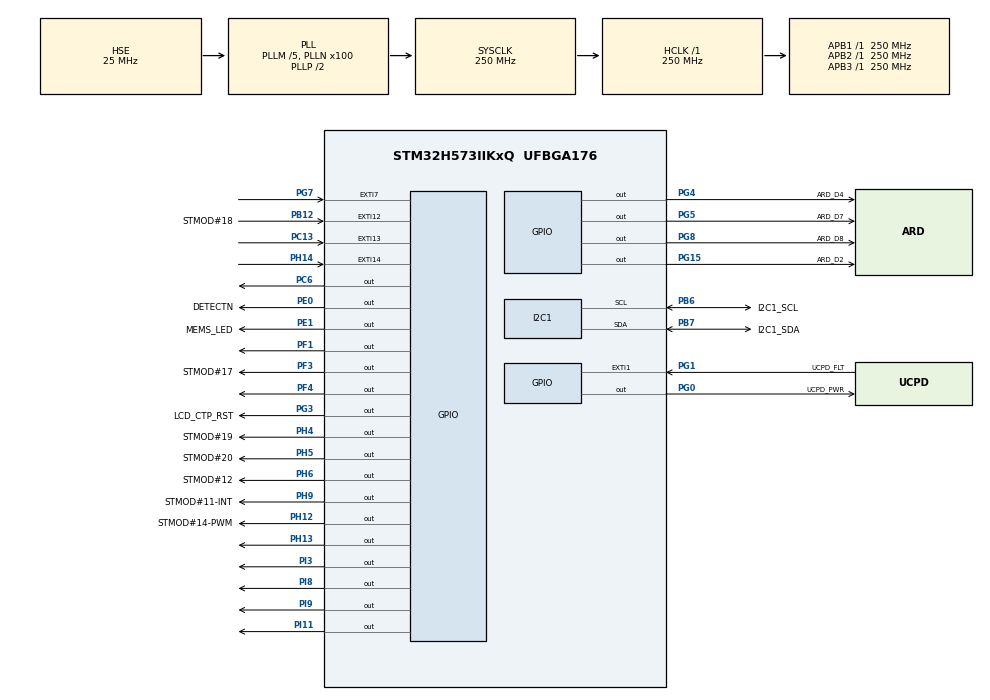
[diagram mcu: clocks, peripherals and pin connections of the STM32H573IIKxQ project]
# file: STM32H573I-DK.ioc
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BOOTPATH.BootPathName=LEGACY
BOOTPATH.UserSelectedBootPath=LEGACY
CORTEX_M33_NS.userName=CORTEX_M33
I2C1.Timing=0x60808CD3
Mcu.Family=STM32H5
Mcu.Name=STM32H573IIKxQ
Mcu.Package=UFBGA176
NVIC.EXTI13_IRQn=true\:0\:0\:false\:false\:true\:false\:true\:true
NVIC.EXTI14_IRQn=true\:0\:0\:false\:false\:true\:false\:true\:true
NVIC.EXTI7_IRQn=true\:0\:0\:false\:false\:true\:false\:true\:true
NVIC.PriorityGroup=NVIC_PRIORITYGROUP_4
PA0.GPIO_Label=ARD_A2
PA0.Signal=ADCx_INP0
PA1.GPIO_Label=RMII_REF_CLK
PA1.Signal=ETH_REF_CLK
PA10.Signal=USART1_RX
PA11.GPIO_Label=USB_FS_N
PA11.Signal=USB_DM
PA12.GPIO_Label=USB_FS_P
PA12.Signal=USB_DP
PA13(JTMS/SWDIO).GPIO_Label=JTMS
PA13(JTMS/SWDIO).Signal=DEBUG_JTMS-SWDIO
PA14(JTCK/SWCLK).GPIO_Label=JTCK
PA14(JTCK/SWCLK).Signal=DEBUG_JTCK-SWCLK
PA15(JTDI).GPIO_Label=JTDI
PA15(JTDI).Signal=DEBUG_JTDI
PA2.GPIO_Label=RMII_MDIO
PA2.Signal=ETH_MDIO
PA3.GPIO_Label=ARD_D10
PA3.Signal=SPI2_NSS
PA4.GPIO_Label=ARD_A1
PA4.Signal=ADCx_INP18
PA5.GPIO_Label=ARD_A3
PA5.Signal=ADCx_INP19
PA6.GPIO_Label=ARD_A4
PA6.Signal=ADCx_INP3
PA7.GPIO_Label=RMII_CRS_DV
PA7.Signal=ETH_CRS_DV
PA8.GPIO_Label=ARD_D9
PA8.Signal=S_TIM1_CH1
PA9.Signal=USART1_TX
PB0.GPIO_Label=ARD_A0
PB0.Signal=ADCx_INP9
PB1.Signal=OCTOSPI1_IO0
PB10.GPIO_Label=ARD_D1
PB10.Signal=USART3_TX
PB11.GPIO_Label=ARD_D0
PB11.Signal=USART3_RX
PB12.GPIO_Label=STMOD\#18
PB12.Signal=GPXTI12
PB13.GPIO_Label=UCPD_CC1
PB13.Signal=UCPD1_CC1
PB14.GPIO_Label=UCPD_CC2
PB14.Signal=UCPD1_CC2
PB15.GPIO_Label=ARD_D11
PB15.Signal=SPI2_MOSI
PB2.Signal=OCTOSPI1_DQS
PB3(JTDO/TRACESWO).GPIO_Label=SWO
PB3(JTDO/TRACESWO).Signal=DEBUG_JTDO-SWO
PB4(NJTRST).GPIO_Label=NJTRST
PB4(NJTRST).Signal=DEBUG_JTRST
PB5.GPIO_Label=ARD_D3
PB5.Signal=S_TIM3_CH2
PB6.GPIO_Label=I2C1_SCL
PB6.Mode=I2C
PB6.Signal=I2C1_SCL
PB7.GPIO_Label=I2C1_SDA
PB7.Mode=I2C
PB7.Signal=I2C1_SDA
PC0.Signal=OCTOSPI1_IO7
PC1.GPIO_Label=RMII_MDC
PC1.Signal=ETH_MDC
PC10.Signal=SDMMC1_D2
PC11.Signal=SDMMC1_D3
PC12.Signal=SDMMC1_CK
PC13.Signal=GPXTI13
PC14-OSC32_IN(OSC32_IN).Signal=RCC_OSC32_IN
PC15-OSC32_OUT(OSC32_OUT).Signal=RCC_OSC32_OUT
PC2.Signal=OCTOSPI1_IO2
PC3.GPIO_Label=PDM_SAI1_SD3
PC3.Signal=SAI1_D3
PC4.GPIO_Label=RMII_RXD0
PC4.Signal=ETH_RXD0
PC5.GPIO_Label=RMII_RXD1
PC5.Signal=ETH_RXD1
PC6.Signal=GPIO_Output
PC7.Signal=FMC_NE1
PC8.Signal=SDMMC1_D0
PC9.Signal=SDMMC1_D1
PD0.Signal=FMC_D2_DA2
PD1.Signal=FMC_D3_DA3
PD10.Signal=FMC_D15_DA15
PD11.Signal=SAI1_CK1
PD12.Signal=OCTOSPI1_IO1
PD13.Signal=OCTOSPI1_IO3
PD14.Signal=FMC_D0_DA0
PD15.Signal=FMC_D1_DA1
PD2.Signal=SDMMC1_CMD
PD3.Signal=FMC_CLK
PD4.Signal=FMC_NOE
PD5.Signal=FMC_NWE
PD6.Signal=SAI1_SD_A
PD8.Signal=FMC_D13_DA13
PD9.Signal=FMC_D14_DA14
PE0.GPIO_Label=DETECTN
PE0.Signal=GPIO_Output
PE1.GPIO_Label=MEMS_LED
PE1.Signal=GPIO_Output
PE10.Signal=FMC_D7_DA7
PE11.Signal=FMC_D8_DA8
PE12.Signal=FMC_D9_DA9
PE13.Signal=FMC_D10_DA10
PE14.Signal=FMC_D11_DA11
PE15.Signal=FMC_D12_DA12
PE2.Signal=DEBUG_TRACECLK
PE3.GPIO_Label=TRACED0
PE3.Signal=DEBUG_TRACED0
PE4.Signal=SAI1_D2
PE5.GPIO_Label=TRACED2
PE5.Signal=DEBUG_TRACED2
PE6.GPIO_Label=TRACED3
PE6.Signal=DEBUG_TRACED3
PE7.Signal=FMC_D4_DA4
PE8.Signal=FMC_D5_DA5
PE9.Signal=FMC_D6_DA6
PF0.Signal=FMC_A0
PF1.Signal=GPIO_Output
PF10.Signal=OCTOSPI1_CLK
PF11.GPIO_Label=STMOD\#13
PF11.Signal=ADC1_INP2
PF12.GPIO_Label=ARD_A5
PF12.Signal=ADC1_INP6
PF13.GPIO_Label=IBUS_SENSE
PF13.Signal=ADC2_INP2
PF14.GPIO_Label=VBUS_SENSE
PF14.Signal=ADC2_INP6
PF3.GPIO_Label=STMOD\#17
PF3.Signal=GPIO_Output
PF4.Signal=GPIO_Output
PG0.GPIO_Label=UCPD_PWR
PG0.Signal=GPIO_Output
PG1.GPIO_Label=UCPD_FLT
PG1.Signal=GPXTI1
PG10.GPIO_Label=SAI2_SD_B
PG10.Signal=SAI2_SD_B
PG11.GPIO_Label=RMII_TX_EN
PG11.Signal=ETH_TX_EN
PG12.GPIO_Label=RMII_TXD1
PG12.Signal=ETH_TXD1
PG13.Signal=ETH_TXD0
PG14.GPIO_Label=TRACED1
PG14.Signal=DEBUG_TRACED1
PG15.GPIO_Label=ARD_D2
PG15.Signal=GPIO_Output
PG3.GPIO_Label=LCD_CTP_RST
PG3.Signal=GPIO_Output
PG4.GPIO_Label=ARD_D4
PG4.Signal=GPIO_Output
PG5.GPIO_Label=ARD_D7
PG5.Signal=GPIO_Output
PG6.Signal=OCTOSPI1_NCS
PG7.Signal=GPXTI7
PG8.GPIO_Label=ARD_D8
PG8.Signal=GPIO_Output
PG9.Signal=OCTOSPI1_IO6
PH0-OSC_IN(PH0).Mode=HSE-DIG-External-Clock-Source
PH0-OSC_IN(PH0).Signal=RCC_OSC_IN
PH10.GPIO_Label=ARD_D6
PH10.Signal=S_TIM5_CH1
PH11.GPIO_Label=ARD_D5
PH11.Signal=S_TIM5_CH2
PH12.GPIO_Label=STMOD\#14-PWM
PH12.Signal=GPIO_Output
PH13.Signal=GPIO_Output
PH14.Signal=GPXTI14
PH2.Signal=OCTOSPI1_IO4
PH3.Signal=OCTOSPI1_IO5
PH4.GPIO_Label=STMOD\#19
PH4.Signal=GPIO_Output
PH5.GPIO_Label=STMOD\#20
PH5.Signal=GPIO_Output
PH6.GPIO_Label=STMOD\#12
PH6.Signal=GPIO_Output
PH7.GPIO_Label=STMOD\#12-RST
PH7.Signal=SPI5_MISO
PH8.GPIO_Label=STMOD\#9-MISOs
PH8.Signal=SPI5_MOSI
PH9.GPIO_Label=STMOD\#11-INT
PH9.Signal=GPIO_Output
PI1.GPIO_Label=ARD_D13
PI1.Signal=SPI2_SCK
PI10.GPIO_Label=RMII_RX_ER
PI10.Signal=ETH_RX_ER
PI11.Signal=GPIO_Output
PI2.GPIO_Label=ARD_D12
PI2.Signal=SPI2_MISO
PI3.Signal=GPIO_Output
PI4.Signal=SAI2_MCLK_A
PI5.Signal=SAI2_SCK_A
PI6.Signal=SAI2_SD_A
PI7.Signal=SAI2_FS_A
PI8.Signal=GPIO_Output
PI9.Signal=GPIO_Output
ProjectManager.HeapSize=0x200
ProjectManager.StackSize=0x400
ProjectManager.TargetToolchain=STM32CubeIDE
RCC.ADCFreq_Value=250000000
RCC.AHBFreq_Value=250000000
RCC.APB1Freq_Value=250000000
RCC.APB1TimFreq_Value=250000000
RCC.APB2Freq_Value=250000000
RCC.APB2TimFreq_Value=250000000
RCC.APB3Freq_Value=250000000
RCC.CSI_VALUE=4000000
RCC.CortexFreq_Value=250000000
RCC.EPOD_VALUE=25000000
RCC.HCLKFreq_Value=250000000
RCC.HSE_VALUE=25000000
RCC.HSI48_VALUE=48000000
RCC.HSIDiv=RCC_HSI_DIV1
RCC.HSI_VALUE=64000000
RCC.LSE_VALUE=32768
RCC.LSIRC_VALUE=32000
RCC.PLL2FRACN=0
RCC.PLL2N=32
RCC.PLL2P=1
RCC.PLLM=5
RCC.PLLN=100
RCC.PLLSourceVirtual=RCC_PLL1_SOURCE_HSE
RCC.SYSCLKFreq_VALUE=250000000
RCC.SYSCLKSource=RCC_SYSCLKSOURCE_PLLCLK
RCC.USBFreq_Value=48000000
RCC.VCOOutputFreq_Value=500000000
SH.ADCx_INP0.0=ADC1_INP0
SH.ADCx_INP18.0=ADC1_INP18
SH.ADCx_INP19.0=ADC1_INP19
SH.ADCx_INP3.0=ADC1_INP3
SH.ADCx_INP9.0=ADC1_INP9
SH.FMC_A0.0=FMC_A0
SH.FMC_CLK.0=FMC_CLK
SH.FMC_D0_DA0.0=FMC_D0
SH.FMC_D10_DA10.0=FMC_D10
SH.FMC_D11_DA11.0=FMC_D11
SH.FMC_D12_DA12.0=FMC_D12
SH.FMC_D13_DA13.0=FMC_D13
SH.FMC_D14_DA14.0=FMC_D14
SH.FMC_D15_DA15.0=FMC_D15
SH.FMC_D1_DA1.0=FMC_D1
SH.FMC_D2_DA2.0=FMC_D2
SH.FMC_D3_DA3.0=FMC_D3
SH.FMC_D4_DA4.0=FMC_D4
SH.FMC_D5_DA5.0=FMC_D5
SH.FMC_D6_DA6.0=FMC_D6
SH.FMC_D7_DA7.0=FMC_D7
SH.FMC_D8_DA8.0=FMC_D8
SH.FMC_D9_DA9.0=FMC_D9
SH.FMC_NOE.0=FMC_NOE
SH.FMC_NWE.0=FMC_NWE
SH.S_TIM1_CH1.0=TIM1_CH1
SH.S_TIM3_CH2.0=TIM3_CH2
SH.S_TIM5_CH1.0=TIM5_CH1
SH.S_TIM5_CH2.0=TIM5_CH2
STM32H573I-DK.AUDIO_IN=true
STM32H573I-DK.AUDIO_OUT=true
STM32H573I-DK.BUTTON=1
STM32H573I-DK.LCD_TC_ON=true
STM32H573I-DK.LD1=true
STM32H573I-DK.LD2=true
STM32H573I-DK.LD3=true
STM32H573I-DK.LD4=true
STM32H573I-DK.OCTOSPI_DEMO=true
STM32H573I-DK.SD_CARD_DEMO=true
STM32H573I-DK.VCP=true
STMicroelectronics.X-CUBE-MEMS1.11.1.0.BoardOoExtensionJjIKS4A1=true
STMicroelectronics.X-CUBE-MEMS1.11.1.0.MEMS1IiApplicationsCcDeviceJjApplication=IKS4A1IiDataLogTerminal
VP_BOOTPATH_VS_BOOTPATH.Mode=BP_Activate
VP_CORTEX_M33_NS_VS_Hclk.Mode=Hclk_Mode
VP_MEMORYMAP_VS_MEMORYMAP.Mode=CurAppReg
VP_PWR_VS_DBSignals.Mode=DisableDeadBatterySignals
VP_PWR_VS_LPOM.Mode=PowerOptimisation
VP_PWR_VS_SECSignals.Mode=Security/Privilege
VP_STM32H573I-DK_VS_BSP_AUDIO.Mode=AUDIO
VP_STM32H573I-DK_VS_BSP_COMMON.Mode=COMMON
VP_STM32H573I-DK_VS_BSP_LCD.Mode=LCD
VP_STM32H573I-DK_VS_BSP_OCTO_SPI.Mode=OSPI
VP_STM32H573I-DK_VS_BSP_SD.Mode=SD
VP_STMicroelectronics.X-CUBE-MEMS1_VS_BoardOoExtensionJjIKS4A1_1.1.0_11.1.0.Mode=BoardOoExtensionJjIKS4A1
VP_STMicroelectronics.X-CUBE-MEMS1_VS_DeviceJjMEMS1IiApplications_11.1.0_11.1.0.Mode=DeviceJjMEMS1IiApplications
board=STM32H573I-DK

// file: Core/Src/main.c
/* USER CODE BEGIN Header */
/**
  ******************************************************************************
  * @file           : main.c
  * @brief          : Main program body
  ******************************************************************************
  * @attention
  *
  * Copyright (c) 2025 STMicroelectronics.
  * All rights reserved.
  *
  * This software is licensed under terms that can be found in the LICENSE file
  * in the root directory of this software component.
  * If no LICENSE file comes with this software, it is provided AS-IS.
  *
  ******************************************************************************
  */
/* USER CODE END Header */
#include "main.h"
#include "app_mems.h"

/* USER CODE BEGIN Includes */
#include <string.h>
/* USER CODE END Includes */

COM_InitTypeDef BspCOMInit;
TS_Init_t   BspTSInit;
BSP_AUDIO_Init_t BspAudioInInit;
BSP_AUDIO_Init_t BspAudioOutInit;
BSP_OSPI_NOR_Init_t BspOSPINORInit;

I2C_HandleTypeDef hi2c1;

void SystemClock_Config(void);
static void MX_GPIO_Init(void);
static void MX_I2C1_Init(void);

int main(void)
{

  /* USER CODE BEGIN 1 */

	//for digikey I2C video
	uint8_t buf[12];

  /* USER CODE END 1 */

  /* MCU Configuration--------------------------------------------------------*/

  /* Reset of all peripherals, Initializes the Flash interface and the Systick. */
  HAL_Init();

  /* Configure the system clock */
  SystemClock_Config();

  /* Initialize all configured peripherals */
  MX_GPIO_Init();
  MX_I2C1_Init();
  MX_MEMS_Init();

  /* Initialize leds */
  BSP_LED_Init(LED_GREEN);
  BSP_LED_Init(LED_ORANGE);
  BSP_LED_Init(LED_RED);
  BSP_LED_Init(LED_BLUE);

  /* Initialize USER push-button, will be used to trigger an interrupt each time it's pressed.*/
  BSP_PB_Init(BUTTON_USER, BUTTON_MODE_EXTI);

  /* Initialize COM1 port (115200, 8 bits (7-bit data + 1 stop bit), no parity */
  BspCOMInit.BaudRate   = 115200;
  BspCOMInit.WordLength = COM_WORDLENGTH_8B;
  BspCOMInit.StopBits   = COM_STOPBITS_1;
  BspCOMInit.Parity     = COM_PARITY_NONE;
  BspCOMInit.HwFlowCtl  = COM_HWCONTROL_NONE;
  if (BSP_COM_Init(COM1, &BspCOMInit) != BSP_ERROR_NONE)
  {
    Error_Handler();
  }

  /* Initialize LCD to black */
  if (BSP_LCD_Init(0, LCD_ORIENTATION_LANDSCAPE) != BSP_ERROR_NONE)
  {
    Error_Handler();
  }

  /* Initialize Touch screen with interrupts */
  BspTSInit.Orientation = TS_ORIENTATION_LANDSCAPE;
  BspTSInit.Accuracy = 5;
  BspTSInit.Width = LCD_DEFAULT_WIDTH;
  BspTSInit.Height = LCD_DEFAULT_HEIGHT;
  if (BSP_TS_Init(0, &BspTSInit) != BSP_ERROR_NONE)
  {
    Error_Handler();
  }
  BSP_TS_EnableIT(0);

  /* Initialize AUDIO IN (Analog) */
  BspAudioInInit.Device = AUDIO_IN_DEVICE_DIGITAL_MIC;
  BspAudioInInit.ChannelsNbr = 2;
  BspAudioInInit.SampleRate = AUDIO_FREQUENCY_16K;
  BspAudioInInit.BitsPerSample = AUDIO_RESOLUTION_16B;
  BspAudioInInit.Volume = 80;
  if (BSP_AUDIO_IN_Init(AUDIO_IN_DEVICE_DIGITAL_MIC, &BspAudioInInit) != BSP_ERROR_NONE)
  {
    Error_Handler();
  }

  /* Initialize AUDIO OUT (Headset) */
  BspAudioOutInit.Device = AUDIO_OUT_DEVICE_HEADPHONE;
  BspAudioOutInit.ChannelsNbr = 2;
  BspAudioOutInit.SampleRate = 16000;
  BspAudioOutInit.BitsPerSample = AUDIO_RESOLUTION_16B;
  BspAudioOutInit.Volume = 60;
  if(BSP_AUDIO_OUT_Init(0, &BspAudioOutInit) != BSP_ERROR_NONE)
  {
    Error_Handler();
  }

  /* Initialize OCTAL NOR memory */
  BspOSPINORInit.InterfaceMode = BSP_OSPI_NOR_OPI_MODE;
  BspOSPINORInit.TransferRate = BSP_OSPI_NOR_DTR_TRANSFER;
  if (BSP_OSPI_NOR_Init(0, &BspOSPINORInit) != BSP_ERROR_NONE)
  {
    Error_Handler();
  }

  /* Initialize SD with detection under interrupt */
  BSP_SD_Init(0);
  BSP_SD_DetectITConfig(0);

  /* Infinite loop */
  /* USER CODE BEGIN WHILE */
  while (1)
  {

	//I2C digikey example, this is done with C not C++ so potential area of improvement / debugging
	//strcpy((char*)buf, "Hello!\r\n");
	//HAL_UART_Transmit(&huart2, buf, strlen((char*)buf), HAL_MAX_DELAY);
	char msg[] = "Hello from STM32H573I-DK VCP!\r\n";
	HAL_UART_Transmit(&huart1, (uint8_t*)msg, sizeof(msg)-1, HAL_MAX_DELAY);
	HAL_Delay(1000);

	//digikey blink led example
	//HAL_GPIO_;TogglePin(GPIOI,GPIO_PIN_9);
	//HAL_Delay(1000);

    /* USER CODE END WHILE */

  MX_MEMS_Process();
  }
}

void SystemClock_Config(void)
{
  RCC_OscInitTypeDef RCC_OscInitStruct = {0};
  RCC_ClkInitTypeDef RCC_ClkInitStruct = {0};

  /** Configure the main internal regulator output voltage
  */
  __HAL_PWR_VOLTAGESCALING_CONFIG(PWR_REGULATOR_VOLTAGE_SCALE0);

  while(!__HAL_PWR_GET_FLAG(PWR_FLAG_VOSRDY)) {}

  /** Initializes the RCC Oscillators according to the specified parameters
  * in the RCC_OscInitTypeDef structure.
  */
  RCC_OscInitStruct.OscillatorType = RCC_OSCILLATORTYPE_HSE;
  RCC_OscInitStruct.HSEState = RCC_HSE_BYPASS_DIGITAL;
  RCC_OscInitStruct.PLL.PLLState = RCC_PLL_ON;
  RCC_OscInitStruct.PLL.PLLSource = RCC_PLL1_SOURCE_HSE;
  RCC_OscInitStruct.PLL.PLLM = 5;
  RCC_OscInitStruct.PLL.PLLN = 100;
  RCC_OscInitStruct.PLL.PLLP = 2;
  RCC_OscInitStruct.PLL.PLLQ = 2;
  RCC_OscInitStruct.PLL.PLLR = 2;
  RCC_OscInitStruct.PLL.PLLRGE = RCC_PLL1_VCIRANGE_2;
  RCC_OscInitStruct.PLL.PLLVCOSEL = RCC_PLL1_VCORANGE_WIDE;
  RCC_OscInitStruct.PLL.PLLFRACN = 0;
  if (HAL_RCC_OscConfig(&RCC_OscInitStruct) != HAL_OK)
  {
    Error_Handler();
  }

  /** Initializes the CPU, AHB and APB buses clocks
  */
  RCC_ClkInitStruct.ClockType = RCC_CLOCKTYPE_HCLK|RCC_CLOCKTYPE_SYSCLK
                              |RCC_CLOCKTYPE_PCLK1|RCC_CLOCKTYPE_PCLK2
                              |RCC_CLOCKTYPE_PCLK3;
  RCC_ClkInitStruct.SYSCLKSource = RCC_SYSCLKSOURCE_PLLCLK;
  RCC_ClkInitStruct.AHBCLKDivider = RCC_SYSCLK_DIV1;
  RCC_ClkInitStruct.APB1CLKDivider = RCC_HCLK_DIV1;
  RCC_ClkInitStruct.APB2CLKDivider = RCC_HCLK_DIV1;
  RCC_ClkInitStruct.APB3CLKDivider = RCC_HCLK_DIV1;

  if (HAL_RCC_ClockConfig(&RCC_ClkInitStruct, FLASH_LATENCY_5) != HAL_OK)
  {
    Error_Handler();
  }

  /** Configure the programming delay
  */
  __HAL_FLASH_SET_PROGRAM_DELAY(FLASH_PROGRAMMING_DELAY_2);
}

static void MX_I2C1_Init(void)
{

  hi2c1.Instance = I2C1;
  hi2c1.Init.Timing = 0x60808CD3;
  hi2c1.Init.OwnAddress1 = 0;
  hi2c1.Init.AddressingMode = I2C_ADDRESSINGMODE_7BIT;
  hi2c1.Init.DualAddressMode = I2C_DUALADDRESS_DISABLE;
  hi2c1.Init.OwnAddress2 = 0;
  hi2c1.Init.OwnAddress2Masks = I2C_OA2_NOMASK;
  hi2c1.Init.GeneralCallMode = I2C_GENERALCALL_DISABLE;
  hi2c1.Init.NoStretchMode = I2C_NOSTRETCH_DISABLE;
  if (HAL_I2C_Init(&hi2c1) != HAL_OK)
  {
    Error_Handler();
  }

  /** Configure Analogue filter
  */
  if (HAL_I2CEx_ConfigAnalogFilter(&hi2c1, I2C_ANALOGFILTER_ENABLE) != HAL_OK)
  {
    Error_Handler();
  }

  /** Configure Digital filter
  */
  if (HAL_I2CEx_ConfigDigitalFilter(&hi2c1, 0) != HAL_OK)
  {
    Error_Handler();
  }

}

static void MX_GPIO_Init(void)
{
  GPIO_InitTypeDef GPIO_InitStruct = {0};

  /* GPIO Ports Clock Enable */
  __HAL_RCC_GPIOB_CLK_ENABLE();
  __HAL_RCC_GPIOG_CLK_ENABLE();
  __HAL_RCC_GPIOI_CLK_ENABLE();
  __HAL_RCC_GPIOE_CLK_ENABLE();
  __HAL_RCC_GPIOA_CLK_ENABLE();
  __HAL_RCC_GPIOC_CLK_ENABLE();
  __HAL_RCC_GPIOF_CLK_ENABLE();
  __HAL_RCC_GPIOH_CLK_ENABLE();

  /*Configure GPIO pin Output Level */
  HAL_GPIO_WritePin(GPIOG, ARD_D2_Pin|ARD_D8_Pin|LCD_CTP_RST_Pin|ARD_D7_Pin
                          |ARD_D4_Pin|UCPD_PWR_Pin, GPIO_PIN_RESET);

  /*Configure GPIO pin Output Level */
  HAL_GPIO_WritePin(GPIOE, MEMS_LED_Pin|DETECTN_Pin, GPIO_PIN_RESET);

  /*Configure GPIO pin Output Level */
  HAL_GPIO_WritePin(STMOD_17_GPIO_Port, STMOD_17_Pin, GPIO_PIN_RESET);

  /*Configure GPIO pin Output Level */
  HAL_GPIO_WritePin(GPIOH, STMOD_11_INT_Pin|STMOD_14_PWM_Pin|STMOD_20_Pin|STMOD_12_Pin
                          |STMOD_19_Pin, GPIO_PIN_RESET);

  /*Configure GPIO pin : ARD_D3_Pin */
  GPIO_InitStruct.Pin = ARD_D3_Pin;
  GPIO_InitStruct.Mode = GPIO_MODE_AF_PP;
  GPIO_InitStruct.Pull = GPIO_NOPULL;
  GPIO_InitStruct.Speed = GPIO_SPEED_FREQ_LOW;
  GPIO_InitStruct.Alternate = GPIO_AF2_TIM3;
  HAL_GPIO_Init(ARD_D3_GPIO_Port, &GPIO_InitStruct);

  /*Configure GPIO pins : ARD_D2_Pin ARD_D8_Pin LCD_CTP_RST_Pin ARD_D7_Pin
                           ARD_D4_Pin UCPD_PWR_Pin */
  GPIO_InitStruct.Pin = ARD_D2_Pin|ARD_D8_Pin|LCD_CTP_RST_Pin|ARD_D7_Pin
                          |ARD_D4_Pin|UCPD_PWR_Pin;
  GPIO_InitStruct.Mode = GPIO_MODE_OUTPUT_PP;
  GPIO_InitStruct.Pull = GPIO_NOPULL;
  GPIO_InitStruct.Speed = GPIO_SPEED_FREQ_LOW;
  HAL_GPIO_Init(GPIOG, &GPIO_InitStruct);

  /*Configure GPIO pin : SAI2_SD_B_Pin */
  GPIO_InitStruct.Pin = SAI2_SD_B_Pin;
  GPIO_InitStruct.Mode = GPIO_MODE_AF_PP;
  GPIO_InitStruct.Pull = GPIO_NOPULL;
  GPIO_InitStruct.Speed = GPIO_SPEED_FREQ_LOW;
  GPIO_InitStruct.Alternate = GPIO_AF10_SAI2;
  HAL_GPIO_Init(SAI2_SD_B_GPIO_Port, &GPIO_InitStruct);

  /*Configure GPIO pins : ARD_D13_Pin ARD_D12_Pin */
  GPIO_InitStruct.Pin = ARD_D13_Pin|ARD_D12_Pin;
  GPIO_InitStruct.Mode = GPIO_MODE_AF_PP;
  GPIO_InitStruct.Pull = GPIO_NOPULL;
  GPIO_InitStruct.Speed = GPIO_SPEED_FREQ_LOW;
  GPIO_InitStruct.Alternate = GPIO_AF5_SPI2;
  HAL_GPIO_Init(GPIOI, &GPIO_InitStruct);

  /*Configure GPIO pins : MEMS_LED_Pin DETECTN_Pin */
  GPIO_InitStruct.Pin = MEMS_LED_Pin|DETECTN_Pin;
  GPIO_InitStruct.Mode = GPIO_MODE_OUTPUT_PP;
  GPIO_InitStruct.Pull = GPIO_NOPULL;
  GPIO_InitStruct.Speed = GPIO_SPEED_FREQ_LOW;
  HAL_GPIO_Init(GPIOE, &GPIO_InitStruct);

  /*Configure GPIO pins : RMII_TXD1_Pin RMII_TX_EN_Pin */
  GPIO_InitStruct.Pin = RMII_TXD1_Pin|RMII_TX_EN_Pin;
  GPIO_InitStruct.Mode = GPIO_MODE_AF_PP;
  GPIO_InitStruct.Pull = GPIO_NOPULL;
  GPIO_InitStruct.Speed = GPIO_SPEED_FREQ_HIGH;
  GPIO_InitStruct.Alternate = GPIO_AF11_ETH;
  HAL_GPIO_Init(GPIOG, &GPIO_InitStruct);

  /*Configure GPIO pin : PE4 */
  GPIO_InitStruct.Pin = GPIO_PIN_4;
  GPIO_InitStruct.Mode = GPIO_MODE_AF_PP;
  GPIO_InitStruct.Pull = GPIO_NOPULL;
  GPIO_InitStruct.Speed = GPIO_SPEED_FREQ_LOW;
  GPIO_InitStruct.Alternate = GPIO_AF2_SAI1;
  HAL_GPIO_Init(GPIOE, &GPIO_InitStruct);

  /*Configure GPIO pins : USB_FS_P_Pin USB_FS_N_Pin */
  GPIO_InitStruct.Pin = USB_FS_P_Pin|USB_FS_N_Pin;
  GPIO_InitStruct.Mode = GPIO_MODE_AF_PP;
  GPIO_InitStruct.Pull = GPIO_NOPULL;
  GPIO_InitStruct.Speed = GPIO_SPEED_FREQ_LOW;
  GPIO_InitStruct.Alternate = GPIO_AF10_USB;
  HAL_GPIO_Init(GPIOA, &GPIO_InitStruct);

  /*Configure GPIO pin : RMII_RX_ER_Pin */
  GPIO_InitStruct.Pin = RMII_RX_ER_Pin;
  GPIO_InitStruct.Mode = GPIO_MODE_AF_PP;
  GPIO_InitStruct.Pull = GPIO_NOPULL;
  GPIO_InitStruct.Speed = GPIO_SPEED_FREQ_HIGH;
  GPIO_InitStruct.Alternate = GPIO_AF11_ETH;
  HAL_GPIO_Init(RMII_RX_ER_GPIO_Port, &GPIO_InitStruct);

  /*Configure GPIO pin : ARD_D9_Pin */
  GPIO_InitStruct.Pin = ARD_D9_Pin;
  GPIO_InitStruct.Mode = GPIO_MODE_AF_PP;
  GPIO_InitStruct.Pull = GPIO_NOPULL;
  GPIO_InitStruct.Speed = GPIO_SPEED_FREQ_LOW;
  GPIO_InitStruct.Alternate = GPIO_AF1_TIM1;
  HAL_GPIO_Init(ARD_D9_GPIO_Port, &GPIO_InitStruct);

  /*Configure GPIO pin : STMOD_17_Pin */
  GPIO_InitStruct.Pin = STMOD_17_Pin;
  GPIO_InitStruct.Mode = GPIO_MODE_OUTPUT_PP;
  GPIO_InitStruct.Pull = GPIO_NOPULL;
  GPIO_InitStruct.Speed = GPIO_SPEED_FREQ_LOW;
  HAL_GPIO_Init(STMOD_17_GPIO_Port, &GPIO_InitStruct);

  /*Configure GPIO pins : RMII_MDC_Pin RMII_RXD0_Pin RMII_RXD1_Pin */
  GPIO_InitStruct.Pin = RMII_MDC_Pin|RMII_RXD0_Pin|RMII_RXD1_Pin;
  GPIO_InitStruct.Mode = GPIO_MODE_AF_PP;
  GPIO_InitStruct.Pull = GPIO_NOPULL;
  GPIO_InitStruct.Speed = GPIO_SPEED_FREQ_HIGH;
  GPIO_InitStruct.Alternate = GPIO_AF11_ETH;
  HAL_GPIO_Init(GPIOC, &GPIO_InitStruct);

  /*Configure GPIO pins : RMII_REF_CLK_Pin RMII_MDIO_Pin RMII_CRS_DV_Pin */
  GPIO_InitStruct.Pin = RMII_REF_CLK_Pin|RMII_MDIO_Pin|RMII_CRS_DV_Pin;
  GPIO_InitStruct.Mode = GPIO_MODE_AF_PP;
  GPIO_InitStruct.Pull = GPIO_NOPULL;
  GPIO_InitStruct.Speed = GPIO_SPEED_FREQ_HIGH;
  GPIO_InitStruct.Alternate = GPIO_AF11_ETH;
  HAL_GPIO_Init(GPIOA, &GPIO_InitStruct);

  /*Configure GPIO pin : STMOD_18_Pin */
  GPIO_InitStruct.Pin = STMOD_18_Pin;
  GPIO_InitStruct.Mode = GPIO_MODE_IT_RISING;
  GPIO_InitStruct.Pull = GPIO_NOPULL;
  HAL_GPIO_Init(STMOD_18_GPIO_Port, &GPIO_InitStruct);

  /*Configure GPIO pins : ARD_A1_Pin ARD_A2_Pin ARD_A4_Pin ARD_A3_Pin */
  GPIO_InitStruct.Pin = ARD_A1_Pin|ARD_A2_Pin|ARD_A4_Pin|ARD_A3_Pin;
  GPIO_InitStruct.Mode = GPIO_MODE_ANALOG;
  GPIO_InitStruct.Pull = GPIO_NOPULL;
  HAL_GPIO_Init(GPIOA, &GPIO_InitStruct);

  /*Configure GPIO pins : ARD_D1_Pin ARD_D0_Pin */
  GPIO_InitStruct.Pin = ARD_D1_Pin|ARD_D0_Pin;
  GPIO_InitStruct.Mode = GPIO_MODE_AF_PP;
  GPIO_InitStruct.Pull = GPIO_NOPULL;
  GPIO_InitStruct.Speed = GPIO_SPEED_FREQ_LOW;
  GPIO_InitStruct.Alternate = GPIO_AF7_USART3;
  HAL_GPIO_Init(GPIOB, &GPIO_InitStruct);

  /*Configure GPIO pins : STMOD_11_INT_Pin STMOD_14_PWM_Pin STMOD_20_Pin STMOD_12_Pin
                           STMOD_19_Pin */
  GPIO_InitStruct.Pin = STMOD_11_INT_Pin|STMOD_14_PWM_Pin|STMOD_20_Pin|STMOD_12_Pin
                          |STMOD_19_Pin;
  GPIO_InitStruct.Mode = GPIO_MODE_OUTPUT_PP;
  GPIO_InitStruct.Pull = GPIO_NOPULL;
  GPIO_InitStruct.Speed = GPIO_SPEED_FREQ_LOW;
  HAL_GPIO_Init(GPIOH, &GPIO_InitStruct);

  /*Configure GPIO pin : ARD_D11_Pin */
  GPIO_InitStruct.Pin = ARD_D11_Pin;
  GPIO_InitStruct.Mode = GPIO_MODE_AF_PP;
  GPIO_InitStruct.Pull = GPIO_NOPULL;
  GPIO_InitStruct.Speed = GPIO_SPEED_FREQ_LOW;
  GPIO_InitStruct.Alternate = GPIO_AF5_SPI2;
  HAL_GPIO_Init(ARD_D11_GPIO_Port, &GPIO_InitStruct);

  /*Configure GPIO pin : PDM_SAI1_SD3_Pin */
  GPIO_InitStruct.Pin = PDM_SAI1_SD3_Pin;
  GPIO_InitStruct.Mode = GPIO_MODE_AF_PP;
  GPIO_InitStruct.Pull = GPIO_NOPULL;
  GPIO_InitStruct.Speed = GPIO_SPEED_FREQ_LOW;
  GPIO_InitStruct.Alternate = GPIO_AF2_SAI1;
  HAL_GPIO_Init(PDM_SAI1_SD3_GPIO_Port, &GPIO_InitStruct);

  /*Configure GPIO pin : ARD_D10_Pin */
  GPIO_InitStruct.Pin = ARD_D10_Pin;
  GPIO_InitStruct.Mode = GPIO_MODE_AF_PP;
  GPIO_InitStruct.Pull = GPIO_NOPULL;
  GPIO_InitStruct.Speed = GPIO_SPEED_FREQ_LOW;
  GPIO_InitStruct.Alternate = GPIO_AF5_SPI2;
  HAL_GPIO_Init(ARD_D10_GPIO_Port, &GPIO_InitStruct);

  /*Configure GPIO pins : ARD_A5_Pin IBUS_SENSE_Pin STMOD_13_Pin VBUS_SENSE_Pin */
  GPIO_InitStruct.Pin = ARD_A5_Pin|IBUS_SENSE_Pin|STMOD_13_Pin|VBUS_SENSE_Pin;
  GPIO_InitStruct.Mode = GPIO_MODE_ANALOG;
  GPIO_InitStruct.Pull = GPIO_NOPULL;
  HAL_GPIO_Init(GPIOF, &GPIO_InitStruct);

  /*Configure GPIO pins : STMOD_9_MISOs_Pin STMOD_12_RST_Pin */
  GPIO_InitStruct.Pin = STMOD_9_MISOs_Pin|STMOD_12_RST_Pin;
  GPIO_InitStruct.Mode = GPIO_MODE_AF_PP;
  GPIO_InitStruct.Pull = GPIO_NOPULL;
  GPIO_InitStruct.Speed = GPIO_SPEED_FREQ_LOW;
  GPIO_InitStruct.Alternate = GPIO_AF5_SPI5;
  HAL_GPIO_Init(GPIOH, &GPIO_InitStruct);

  /*Configure GPIO pins : ARD_D6_Pin ARD_D5_Pin */
  GPIO_InitStruct.Pin = ARD_D6_Pin|ARD_D5_Pin;
  GPIO_InitStruct.Mode = GPIO_MODE_AF_PP;
  GPIO_InitStruct.Pull = GPIO_NOPULL;
  GPIO_InitStruct.Speed = GPIO_SPEED_FREQ_LOW;
  GPIO_InitStruct.Alternate = GPIO_AF2_TIM5;
  HAL_GPIO_Init(GPIOH, &GPIO_InitStruct);

  /*Configure GPIO pins : UCPD_CC2_Pin ARD_A0_Pin UCPD_CC1_Pin */
  GPIO_InitStruct.Pin = UCPD_CC2_Pin|ARD_A0_Pin|UCPD_CC1_Pin;
  GPIO_InitStruct.Mode = GPIO_MODE_ANALOG;
  GPIO_InitStruct.Pull = GPIO_NOPULL;
  HAL_GPIO_Init(GPIOB, &GPIO_InitStruct);

  /*Configure GPIO pin : UCPD_FLT_Pin */
  GPIO_InitStruct.Pin = UCPD_FLT_Pin;
  GPIO_InitStruct.Mode = GPIO_MODE_IT_RISING;
  GPIO_InitStruct.Pull = GPIO_NOPULL;
  HAL_GPIO_Init(UCPD_FLT_GPIO_Port, &GPIO_InitStruct);

}

void Error_Handler(void)
{
  __disable_irq();
  while (1)
  {
  }
}
